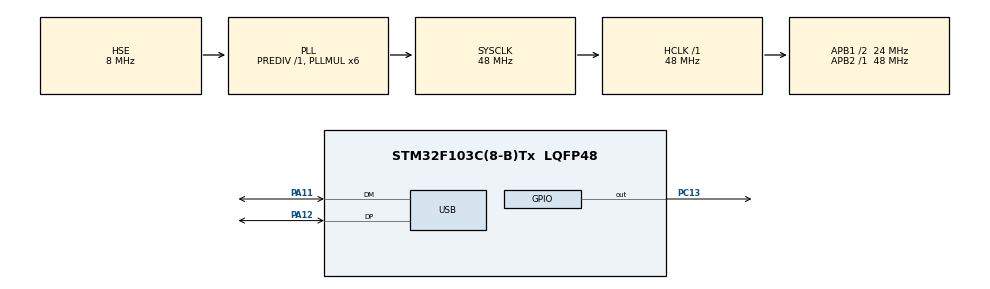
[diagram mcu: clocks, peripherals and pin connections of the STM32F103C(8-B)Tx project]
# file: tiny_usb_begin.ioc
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Mcu.Family=STM32F1
Mcu.Name=STM32F103C(8-B)Tx
Mcu.Package=LQFP48
NVIC.PriorityGroup=NVIC_PRIORITYGROUP_4
NVIC.USB_HP_CAN1_TX_IRQn=true\:0\:0\:false\:false\:true\:true\:true\:true
NVIC.USB_LP_CAN1_RX0_IRQn=true\:0\:0\:false\:false\:true\:true\:true\:true
PA11.Mode=Device
PA11.Signal=USB_DM
PA12.Mode=Device
PA12.Signal=USB_DP
PA13.Mode=Serial_Wire
PA13.Signal=SYS_JTMS-SWDIO
PA14.Mode=Serial_Wire
PA14.Signal=SYS_JTCK-SWCLK
PC13-TAMPER-RTC.GPIO_Speed=GPIO_SPEED_FREQ_HIGH
PC13-TAMPER-RTC.PinState=GPIO_PIN_SET
PC13-TAMPER-RTC.Signal=GPIO_Output
PD0-OSC_IN.Mode=HSE-External-Oscillator
PD0-OSC_IN.Signal=RCC_OSC_IN
PD1-OSC_OUT.Mode=HSE-External-Oscillator
PD1-OSC_OUT.Signal=RCC_OSC_OUT
ProjectManager.HeapSize=0x200
ProjectManager.StackSize=0x400
ProjectManager.TargetToolchain=STM32CubeIDE
RCC.AHBFreq_Value=48000000
RCC.APB1CLKDivider=RCC_HCLK_DIV2
RCC.APB1Freq_Value=24000000
RCC.APB1TimFreq_Value=48000000
RCC.APB2Freq_Value=48000000
RCC.APB2TimFreq_Value=48000000
RCC.HCLKFreq_Value=48000000
RCC.PLLMUL=RCC_PLL_MUL6
RCC.PLLSourceVirtual=RCC_PLLSOURCE_HSE
RCC.SYSCLKFreq_VALUE=48000000
RCC.SYSCLKSource=RCC_SYSCLKSOURCE_PLLCLK
RCC.USBFreq_Value=48000000
board=custom

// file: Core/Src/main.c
/* USER CODE BEGIN Header */
/**
  ******************************************************************************
  * @file           : main.c
  * @brief          : Main program body
  ******************************************************************************
  * @attention
  *
  * Copyright (c) 2025 STMicroelectronics.
  * All rights reserved.
  *
  * This software is licensed under terms that can be found in the LICENSE file
  * in the root directory of this software component.
  * If no LICENSE file comes with this software, it is provided AS-IS.
  *
  ******************************************************************************
  */
/* USER CODE END Header */
#include "main.h"

/* USER CODE BEGIN Includes */
#include "tusb.h"
/* USER CODE END Includes */

PCD_HandleTypeDef hpcd_USB_FS;

void SystemClock_Config(void);
static void MX_GPIO_Init(void);
static void MX_USB_PCD_Init(void);
/* USER CODE BEGIN PFP */
void tud_vendor_rx_cb(uint8_t itf, uint8_t const* buffer, uint16_t bufsize)
{
    uint8_t buf[64];
    uint32_t count = tud_vendor_read(buf, bufsize);
    // do something with received bytes
}

void tud_vendor_tx_done_cb(uint8_t itf)
{
    // TX finished, may queue next packet
}

/* USER CODE END PFP */

int main(void)
{

  /* MCU Configuration--------------------------------------------------------*/

  /* Reset of all peripherals, Initializes the Flash interface and the Systick. */
  HAL_Init();

  /* Configure the system clock */
  SystemClock_Config();

  /* Initialize all configured peripherals */
  MX_GPIO_Init();
  MX_USB_PCD_Init();
  /* USER CODE BEGIN 2 */
  tusb_init();   // initialize TinyUSB stack

  /* USER CODE END 2 */

  /* Infinite loop */
  /* USER CODE BEGIN WHILE */
  while (1)
  {
	  tud_task();   // handle USB events
    /* USER CODE END WHILE */

  }
}

void SystemClock_Config(void)
{
  RCC_OscInitTypeDef RCC_OscInitStruct = {0};
  RCC_ClkInitTypeDef RCC_ClkInitStruct = {0};
  RCC_PeriphCLKInitTypeDef PeriphClkInit = {0};

  /** Initializes the RCC Oscillators according to the specified parameters
  * in the RCC_OscInitTypeDef structure.
  */
  RCC_OscInitStruct.OscillatorType = RCC_OSCILLATORTYPE_HSE;
  RCC_OscInitStruct.HSEState = RCC_HSE_ON;
  RCC_OscInitStruct.HSEPredivValue = RCC_HSE_PREDIV_DIV1;
  RCC_OscInitStruct.HSIState = RCC_HSI_ON;
  RCC_OscInitStruct.PLL.PLLState = RCC_PLL_ON;
  RCC_OscInitStruct.PLL.PLLSource = RCC_PLLSOURCE_HSE;
  RCC_OscInitStruct.PLL.PLLMUL = RCC_PLL_MUL6;
  if (HAL_RCC_OscConfig(&RCC_OscInitStruct) != HAL_OK)
  {
    Error_Handler();
  }

  /** Initializes the CPU, AHB and APB buses clocks
  */
  RCC_ClkInitStruct.ClockType = RCC_CLOCKTYPE_HCLK|RCC_CLOCKTYPE_SYSCLK
                              |RCC_CLOCKTYPE_PCLK1|RCC_CLOCKTYPE_PCLK2;
  RCC_ClkInitStruct.SYSCLKSource = RCC_SYSCLKSOURCE_PLLCLK;
  RCC_ClkInitStruct.AHBCLKDivider = RCC_SYSCLK_DIV1;
  RCC_ClkInitStruct.APB1CLKDivider = RCC_HCLK_DIV2;
  RCC_ClkInitStruct.APB2CLKDivider = RCC_HCLK_DIV1;

  if (HAL_RCC_ClockConfig(&RCC_ClkInitStruct, FLASH_LATENCY_1) != HAL_OK)
  {
    Error_Handler();
  }
  PeriphClkInit.PeriphClockSelection = RCC_PERIPHCLK_USB;
  PeriphClkInit.UsbClockSelection = RCC_USBCLKSOURCE_PLL;
  if (HAL_RCCEx_PeriphCLKConfig(&PeriphClkInit) != HAL_OK)
  {
    Error_Handler();
  }
}

static void MX_USB_PCD_Init(void)
{

  hpcd_USB_FS.Instance = USB;
  hpcd_USB_FS.Init.dev_endpoints = 8;
  hpcd_USB_FS.Init.speed = PCD_SPEED_FULL;
  hpcd_USB_FS.Init.low_power_enable = DISABLE;
  hpcd_USB_FS.Init.lpm_enable = DISABLE;
  hpcd_USB_FS.Init.battery_charging_enable = DISABLE;
  if (HAL_PCD_Init(&hpcd_USB_FS) != HAL_OK)
  {
    Error_Handler();
  }

}

static void MX_GPIO_Init(void)
{
  LL_GPIO_InitTypeDef GPIO_InitStruct = {0};

  /* GPIO Ports Clock Enable */
  LL_APB2_GRP1_EnableClock(LL_APB2_GRP1_PERIPH_GPIOC);
  LL_APB2_GRP1_EnableClock(LL_APB2_GRP1_PERIPH_GPIOD);
  LL_APB2_GRP1_EnableClock(LL_APB2_GRP1_PERIPH_GPIOA);

  /**/
  LL_GPIO_SetOutputPin(GPIOC, LL_GPIO_PIN_13);

  /**/
  GPIO_InitStruct.Pin = LL_GPIO_PIN_13;
  GPIO_InitStruct.Mode = LL_GPIO_MODE_OUTPUT;
  GPIO_InitStruct.Speed = LL_GPIO_SPEED_FREQ_HIGH;
  GPIO_InitStruct.OutputType = LL_GPIO_OUTPUT_PUSHPULL;
  LL_GPIO_Init(GPIOC, &GPIO_InitStruct);

}

void Error_Handler(void)
{
  __disable_irq();
  while (1)
  {
  }
}
